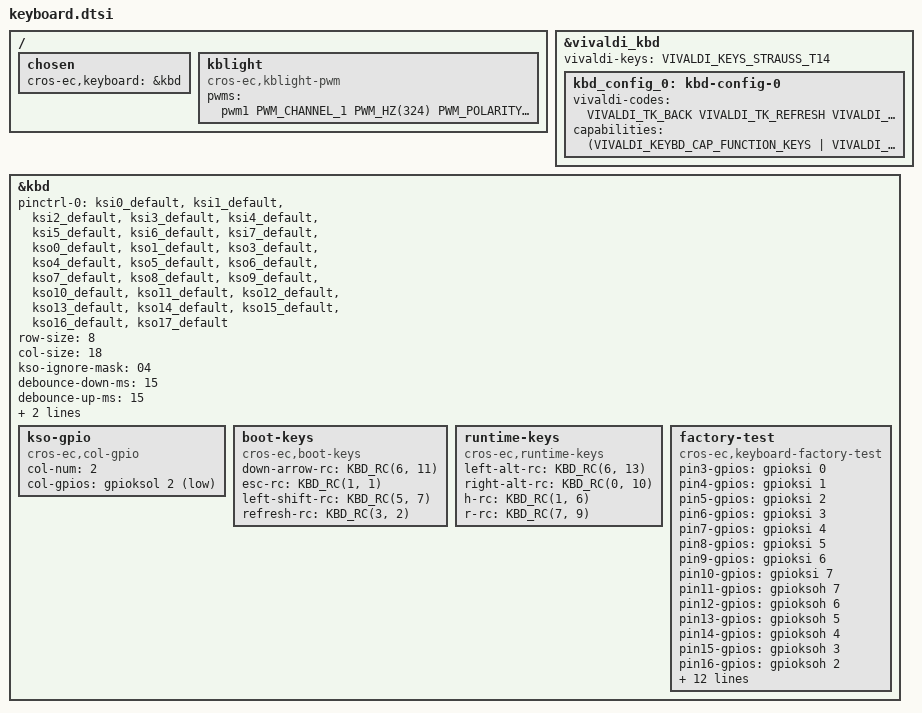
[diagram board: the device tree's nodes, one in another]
/* Copyright 2025 The ChromiumOS Authors
 * Use of this source code is governed by a BSD-style license that can be
 * found in the LICENSE file.
 */

/ {
	chosen {
		cros-ec,keyboard = &kbd;
	};

	kblight: kblight {
		compatible = "cros-ec,kblight-pwm";
		pwms = <&pwm1 PWM_CHANNEL_1 PWM_HZ(324) PWM_POLARITY_NORMAL>;
	};

};

&vivaldi_kbd {
	vivaldi-keys = <VIVALDI_KEYS_STRAUSS_T14>;

	kbd_config_0: kbd-config-0 {
		vivaldi-codes = <
			VIVALDI_TK_BACK               /* T1 */
			VIVALDI_TK_REFRESH            /* T2 */
			VIVALDI_TK_FULLSCREEN         /* T3 */
			VIVALDI_TK_OVERVIEW           /* T4 */
			VIVALDI_TK_SNAPSHOT           /* T5 */
			VIVALDI_TK_BRIGHTNESS_DOWN    /* T6 */
			VIVALDI_TK_BRIGHTNESS_UP      /* T7 */
			VIVALDI_TK_KBD_BKLIGHT_TOGGLE /* T8 */
			VIVALDI_TK_DICTATE            /* T9 */
			VIVALDI_TK_ACCESSIBILITY      /* T10 */
			VIVALDI_TK_MICMUTE            /* T11 */
			VIVALDI_TK_VOL_MUTE           /* T12 */
			VIVALDI_TK_VOL_DOWN           /* T13 */
			VIVALDI_TK_VOL_UP             /* T14 */
		>;
		capabilities = <(VIVALDI_KEYBD_CAP_FUNCTION_KEYS |
				VIVALDI_KEYBD_CAP_SCRNLOCK_KEY |
				VIVALDI_KEYBD_CAP_ASSISTANT_KEY)
		>;
	};
};

&kbd {
	status = "okay";

	pinctrl-0 = <
		&ksi0_default
		&ksi1_default
		&ksi2_default
		&ksi3_default
		&ksi4_default
		&ksi5_default
		&ksi6_default
		&ksi7_default
		&kso0_default
		&kso1_default
		&kso3_default
		&kso4_default
		&kso5_default
		&kso6_default
		&kso7_default
		&kso8_default
		&kso9_default
		&kso10_default
		&kso11_default
		&kso12_default
		&kso13_default
		&kso14_default
		&kso15_default
		&kso16_default
		&kso17_default
	>;

	pinctrl-names = "default";
	row-size = <8>;
	col-size = <18>;
	kso-ignore-mask = <04>;
	debounce-down-ms = <15>;
	debounce-up-ms = <15>;
	actual-key-mask = <
		0x08  /* C0 */
		0xff  /* C1 */
		0xff  /* C2 */
		0xff  /* C3 */
		0xff  /* C4 */
		0xff  /* C5 */
		0xff  /* C6 */
		0xa0  /* C7 */
		0xff  /* C8 */
		0xff  /* C9 */
		0x01  /* C10 */
		0xff  /* C11 */
		0xff  /* C12 */
		0x40  /* C13 */
		0x0a  /* C14 */
		0x40  /* C15 */
		0x01  /* C16 */
		0xc4  /* C17 */
	>;

	kso-gpio {
		compatible = "cros-ec,col-gpio";
		col-num = <2>;
		col-gpios = <&gpioksol 2 GPIO_ACTIVE_LOW>;
	};

	boot-keys {
		compatible = "cros-ec,boot-keys";
		down-arrow-rc = <KBD_RC(6, 11)>;
		esc-rc = <KBD_RC(1, 1)>;
		left-shift-rc = <KBD_RC(5, 7)>;
		refresh-rc = <KBD_RC(3, 2)>;
	};

	runtime-keys {
		compatible = "cros-ec,runtime-keys";
		left-alt-rc = <KBD_RC(6, 13)>;
		right-alt-rc = <KBD_RC(0, 10)>;
		h-rc = <KBD_RC(1, 6)>;
		r-rc = <KBD_RC(7, 9)>;
	};

	factory-test {
		compatible = "cros-ec,keyboard-factory-test";

		pin3-gpios = <&gpioksi 0 GPIO_ACTIVE_HIGH>;
		pin4-gpios = <&gpioksi 1 GPIO_ACTIVE_HIGH>;
		pin5-gpios = <&gpioksi 2 GPIO_ACTIVE_HIGH>;
		pin6-gpios = <&gpioksi 3 GPIO_ACTIVE_HIGH>;
		pin7-gpios = <&gpioksi 4 GPIO_ACTIVE_HIGH>;
		pin8-gpios = <&gpioksi 5 GPIO_ACTIVE_HIGH>;
		pin9-gpios = <&gpioksi 6 GPIO_ACTIVE_HIGH>;
		pin10-gpios = <&gpioksi 7 GPIO_ACTIVE_HIGH>;

		pin11-gpios = <&gpioksoh 7 GPIO_ACTIVE_HIGH>;
		pin12-gpios = <&gpioksoh 6 GPIO_ACTIVE_HIGH>;
		pin13-gpios = <&gpioksoh 5 GPIO_ACTIVE_HIGH>;
		pin14-gpios = <&gpioksoh 4 GPIO_ACTIVE_HIGH>;
		pin15-gpios = <&gpioksoh 3 GPIO_ACTIVE_HIGH>;
		pin16-gpios = <&gpioksoh 2 GPIO_ACTIVE_HIGH>;
		pin17-gpios = <&gpioksoh 1 GPIO_ACTIVE_HIGH>;
		pin18-gpios = <&gpioksoh 0 GPIO_ACTIVE_HIGH>;

		pin19-gpios = <&gpioksol 7 GPIO_ACTIVE_HIGH>;
		pin20-gpios = <&gpioksol 6 GPIO_ACTIVE_HIGH>;
		pin21-gpios = <&gpioksol 5 GPIO_ACTIVE_HIGH>;
		pin22-gpios = <&gpioksol 4 GPIO_ACTIVE_HIGH>;
		pin23-gpios = <&gpioksol 3 GPIO_ACTIVE_HIGH>;
		pin24-gpios = <&gpioksol 2 GPIO_ACTIVE_HIGH>;
		pin25-gpios = <&gpioksol 1 GPIO_ACTIVE_HIGH>;
		pin26-gpios = <&gpioksol 0 GPIO_ACTIVE_HIGH>;

		pin27-gpios = <&gpioc 5 GPIO_ACTIVE_HIGH>;
		pin28-gpios = <&gpioc 3 GPIO_ACTIVE_HIGH>;
	};
};
